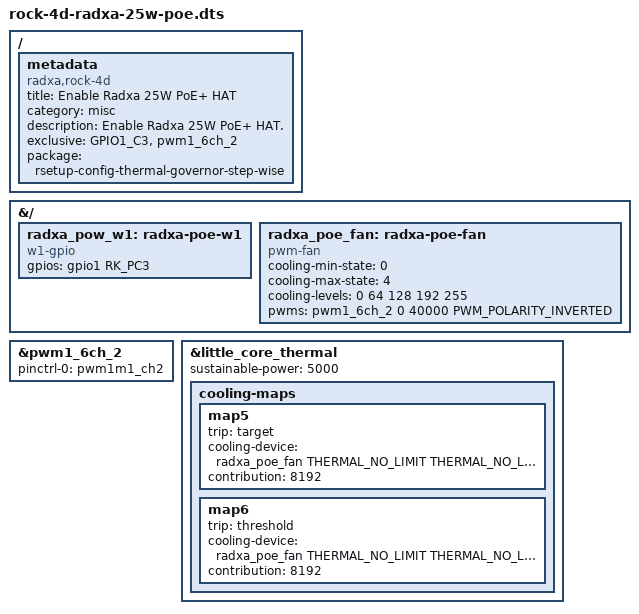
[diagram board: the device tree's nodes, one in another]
/dts-v1/;
/plugin/;

#include <dt-bindings/gpio/gpio.h>
#include <dt-bindings/pinctrl/rockchip.h>
#include <dt-bindings/pwm/pwm.h>
#include <dt-bindings/thermal/thermal.h>

/ {
	metadata {
		title = "Enable Radxa 25W PoE+ HAT";
		category = "misc";
		compatible = "radxa,rock-4d";
		description = "Enable Radxa 25W PoE+ HAT.";
		exclusive = "GPIO1_C3", "pwm1_6ch_2";
		package = "rsetup-config-thermal-governor-step-wise";
	};
};

&{/} {
	radxa_pow_w1: radxa-poe-w1 {
		compatible = "w1-gpio";
		gpios = <&gpio1 RK_PC3 GPIO_ACTIVE_HIGH>;
		status = "okay";
	};

	radxa_poe_fan: radxa-poe-fan {
		compatible = "pwm-fan";
		#cooling-cells = <2>;
		cooling-min-state = <0>;
		cooling-max-state = <4>;
		cooling-levels = <0 64 128 192 255>;
		pwms = <&pwm1_6ch_2 0 40000 PWM_POLARITY_INVERTED>;
	};
};

&pwm1_6ch_2 {
	pinctrl-0 = <&pwm1m1_ch2>;
	status = "okay";
};

&little_core_thermal {
	sustainable-power = <5000>; /* milliwatts */
	cooling-maps {
		map5 {
			trip = <&target>;
			cooling-device =
				<&radxa_poe_fan THERMAL_NO_LIMIT THERMAL_NO_LIMIT>;
			contribution = <8192>;
		};
		map6 {
			trip = <&threshold>;
			cooling-device =
				<&radxa_poe_fan THERMAL_NO_LIMIT THERMAL_NO_LIMIT>;
			contribution = <8192>;
		};
	};
};

